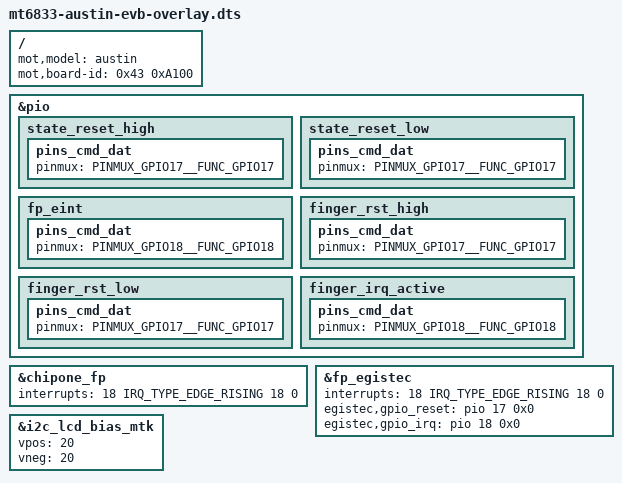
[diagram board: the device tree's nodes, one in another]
/* Copyright (c) 2019, Motorola Mobility Inc. All rights reserved.
 *
 * This program is free software; you can redistribute it and/or modify
 * it under the terms of the GNU General Public License version 2 and
 * only version 2 as published by the Free Software Foundation.
 *
 * This program is distributed in the hope that it will be useful,
 * but WITHOUT ANY WARRANTY; without even the implied warranty of
 * MERCHANTABILITY or FITNESS FOR A PARTICULAR PURPOSE.  See the
 * GNU General Public License for more details.
 */

/dts-v1/;
/plugin/;

#include "mediatek/mt6833-austin-common-overlay.dtsi"
#include "mediatek/cust_mt6833_touch_720x1600.dtsi"

/* Board match root node */
/ {
	fragment@model {
		target-path = "/";
		__overlay__ {
			mot,model = "austin";
			mot,board-id = <0x43 0xA100>;
		};
	};
};

&pio {
	state_reset_high {
		pins_cmd_dat {
			pinmux = <PINMUX_GPIO17__FUNC_GPIO17>;
		};
	};

	state_reset_low {
		pins_cmd_dat {
			pinmux = <PINMUX_GPIO17__FUNC_GPIO17>;
		};
	};

	fp_eint {
		pins_cmd_dat {
			pinmux = <PINMUX_GPIO18__FUNC_GPIO18>;
		};
	};

	finger_rst_high {
		pins_cmd_dat {
			pinmux = <PINMUX_GPIO17__FUNC_GPIO17>;
		};
	};
	finger_rst_low {
		pins_cmd_dat {
			pinmux = <PINMUX_GPIO17__FUNC_GPIO17>;
		};
	};

	finger_irq_active {
		pins_cmd_dat {
			pinmux = <PINMUX_GPIO18__FUNC_GPIO18>;
		};
	};

};

&chipone_fp {
	interrupts = <18 IRQ_TYPE_EDGE_RISING 18 0>;
};

&fp_egistec {
	interrupts = <18 IRQ_TYPE_EDGE_RISING 18 0>;
	egistec,gpio_reset = <&pio 17 0x0>;
	egistec,gpio_irq = <&pio 18 0x0>;
};
#include <austin_evb/cust.dtsi>

&i2c_lcd_bias_mtk {
	vpos = <20>;//4.0v+20*100mv=6v
	vneg = <20>;
};
/*End of this file, DO NOT ADD ANYTHING HERE*/
